# SN32F400 register map
Vendor: SONiX Technology Co., Ltd.; Series: SN32F400; File version: 1.1
CPU: CM0 r0p0, little endian, no MPU, no FPU, 2 interrupt priority bits
Registers are 32-bit, read-write, reset 0x0 unless marked. A register's access mark holds for its fields unless they carry their own. Offsets are from the block's base; [hi:lo] are bit positions; {n}, {i} and the like mark numbered series; 'fields as' and 'values as' point back to an identical list.

## SN_RTC — Real-time Clock
Base 0x40012000
0x00 CTRL — Offset:0x00 RTC Control register
  [0] RTCEN — RTC enable
    0=Disable RTC; 1=Enable RTC
0x04 CLKS — Offset:0x04 RTC Clock Source register
  [0] CLKSEL — RTC clock source
    0=ILRC (RTC clock source=ILRC); 1=ELS XTAL (RTC clock source=ELS XTAL)
0x08 IE — Offset:0x08 RTC Interrupt Enable register
  [0] SECIE — Second interrupt enable
    0=Disable second interrupt; 1=Enable second interrupt
0x0C RIS ro — Offset:0x0C RTC Raw Interrupt Status register
  [0] SECIF — Second interrupt flag
    0=No (No second interrupt); 1=Met (Second interrupt is triggered when SECIE=1)
0x10 IC wo — Offset:0x10 RTC Interrupt Clear register
  [0] SECIC — Second interrupt flag clear
    0=None (No effect); 1=Clear second interrupt flag
0x14 SECCNTV reset 0x8000 — Offset:0x14 RTC Second Counter Reload Value register
  [19:0] SECCNTV — RTC Second Counter Reload value
0x18 SECCNT ro — Offset:0x18 RTC Second Counter register
  [31:0] SECCNT — RTC Second counter

## SN_OPA — OP Amplifier
Base 0x4002A000
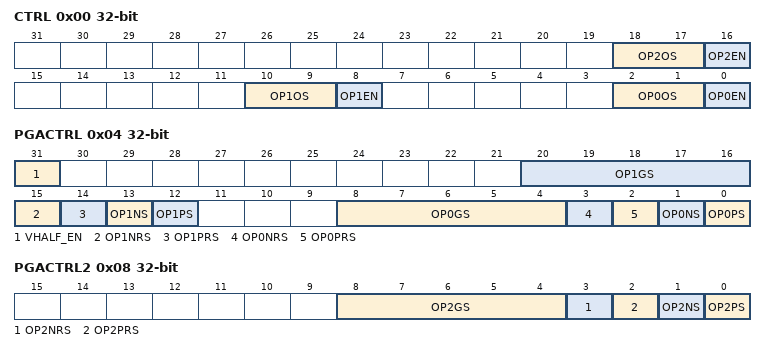
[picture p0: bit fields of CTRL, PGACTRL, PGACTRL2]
0x00 CTRL — Offset:0x0 OPA Control register
  [18:17] OP2OS — OPA2 output select bits
    0=OP2O (Output to OP2O); 1=AIN21/CM2P (Output to AIN21 and CM2P)
  [16] OP2EN — OPA2 enable bit
    0=Disable OPA2; 1=Enable OPA2
  [10:9] OP1OS — OPA1 output select bits
    0=OP1O (Output to OP1O); 1=AIN20/CM1P (Output to AIN20 and CM1P)
  [8] OP1EN — OPA1 enable bit
    0=Disable OPA1; 1=Enable OPA1
  [2:1] OP0OS — OPA0 output select bits
    0=OP0O (Output to OP0O); 1=AIN19/CM0P (Output to AIN19 and CM0P)
  [0] OP0EN — OPA0 enable bit
    0=Disable OPA0; 1=Enable OPA0
0x04 PGACTRL — Offset:0x4 OPA PGA Control register
  [31] VHALF_EN — VDD/2 bias enable bit
    0=Disable VDD/2 bias; 1=Enable VDD/2 bias
  [20:16] OP1GS — OPA1 gain select bits
    0=Gain = 1X; {v}={v+1}X (Gain = {v+1}X) (v=1..8); 9=Gain = 10X; 10=Gain = 11X; {v}={v+1}X (Gain = {v+1}X) (v=11..31)
  [15] OP1NRS — OPA1 negative input resistor select bit
    0=10K (10K Ohm); 1=Short the resistor
  [14] OP1PRS — OPA1 positive input resistor select bit
    0=10K (10K Ohm); 1=Short the resistor
  [13] OP1NS — OPA1 negative input feedback enable bit
    0=Disable OPA1 negative input feedback; 1=Enable OPA1 negative input feedback
  [12] OP1PS — OPA1 positive input bias enable bit
    0=Disable OPA1 positive input bias; 1=Enable OPA1 positive input bias
  [8:4] OP0GS — OPA0 gain select bits
    values as OP1GS
  [3] OP0NRS — OPA0 negative input resistor select bit
    0=10K (10K Ohm); 1=Short the resistor
  [2] OP0PRS — OPA0 positive input resistor select bit
    0=10K (10K Ohm); 1=Short the resistor
  [1] OP0NS — OPA0 negative input feedback enable bit
    0=Disable OPA0 negative input feedback; 1=Enable OPA0 negative input feedback
  [0] OP0PS — OPA0 positive input bias enable bit
    0=Disable OPA0 positive input bias; 1=Enable OPA0 positive input bias
0x08 PGACTRL2 — Offset:0x8 OPA PGA Control register 2
  [8:4] OP2GS — OPA2 gain select bits
    values as PGACTRL.OP1GS
  [3] OP2NRS — OPA2 negative input resistor select bit
    0=10K (10K Ohm); 1=Short the resistor
  [2] OP2PRS — OPA2 positive input resistor select bit
    0=10K (10K Ohm); 1=Short the resistor
  [1] OP2NS — OPA2 negative input feedback enable bit
    0=Disable OPA2 negative input feedback; 1=Enable OPA2 negative input feedback
  [0] OP2PS — OPA2 positive input bias enable bit
    0=Disable OPA2 positive input bias; 1=Enable OPA2 positive input bias

## SN_PMU — Power Management Unit
Base 0x40032000
0x40 CTRL — Offset:0x40 PMU Control register
  [2:0] MODE — Low Power mode selection
    0=Normal mode; 2=Deep-sleep mode (WFI instruction will make MCU enter Deep-sleep mode); 4=Sleep mode (WFI instruction will make MCU enter Sleep mode)
